# YC3122 register map
Series: ARMCM0; File version: 1.0
CPU: CM0 r1p0, little endian, no MPU, no FPU, 8 interrupt priority bits
Registers are 32-bit, read-write, reset 0x0 unless marked. A register's access mark holds for its fields unless they carry their own. Offsets are from the block's base; [hi:lo] are bit positions; {n}, {i} and the like mark numbered series.

## MMPU
Base 0x000D8080
0x00 CTRL_ID
  [31:0] VAL ro — MPU ID
0x04 CTRL
  [0] VAL — MPU使能
0x0C CTRL_FSR
  [31:0] VAL — [4:2] fault region [1:0] fault status
0x10 CTRL_FAR
  [31:0] VAL — fault address
0x14 PROTECTION 16-bit
  [15:0] VAL — protection15：0. 00：no access. 01：private only. 10：private + user read only. 11：Full Access
0x18 USER_START
  [31:0] VAL — 用户程序起始地址
{0x40+4i} REGION_BASE{i} (i=0..7)
  [31:0] VAL — [0]regionx_enable [20:6]. BASEx_REG
{0x60+4i} REGION_LIMIT{i} (i=0..7)
  [31:0] VAL — [20:6] LIMIT{i}_REG

## MWDT
Base 0x000F0000
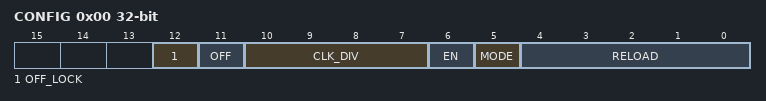
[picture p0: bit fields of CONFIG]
0x00 CONFIG
  [12] OFF_LOCK — wdt_off_lock. 1: wdt_off不起作用 0: wdt_off起作用
  [11] OFF — 关闭wdt wdt_off_lock为0,并且wdt_on为0时,设 置wdt_off为1,再设置wdt_off为0,可关闭w dt
  [10:7] CLK_DIV — hclk预分频,最大16分频,实际使用的时钟频率 是clk/(wdt_clk_div+1)
  [6] EN — 0 :WDT功能关闭. 1: WDT 功能打开.
  [5] MODE — 0 :复位 1:中断
  [4:0] RELOAD — WDT计数时长为(2^(wdt_preset-1 ))个hclk_div时钟周期
0x04 CNT
  [31:0] CNT ro — WDT CNT
0x08 IRQ_STATUS — WDT IRQ STATUS
  [0] STATE ro
0x08 KICK (alternate view of IRQ_STATUS) — WDT KICK, 必须写 0x5937
  [31:0] VALUE wo — WDT KICK,必须写 0x5937
0x0C CLEAR
  [0] CLEAR — 向这个寄存器中写1清除WDT 中断

## MTIM — 32 TIMER
Base 0x000F0C00
{0x0+4i} PERIOD[{i}] (i=0..17)
  [31:0] period
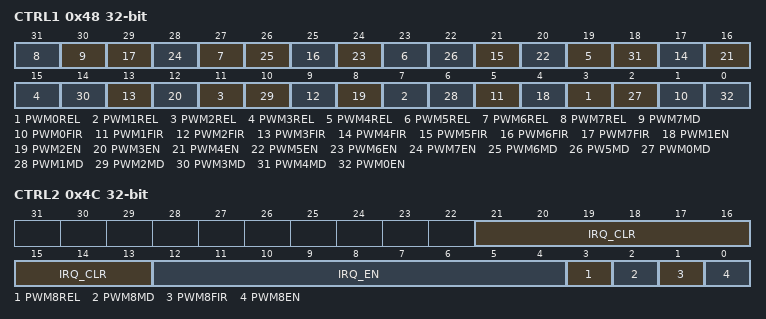
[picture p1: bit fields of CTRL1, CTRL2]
0x48 CTRL1 — pwm Control Register(0~7)
  [4n+3] PWM{n}REL (n=0..7) — TIMER AUTO RELOAD
  [30] PWM7MD — TIMER mode
  [4n+1] PWM{n}FIR (n=0..7) — TIMER initial level
  [4n] PWM{n}EN (n=1..7) — Enable or disable TIMER{n}
  [26] PWM6MD — TIMER mode
  [22] PW5MD — TIMER mode
  [4n+2] PWM{n}MD (n=0..4) — TIMER mode
  [0] PWM0EN — Enable or disable TIMER
0x4C CTRL2 — pwm Control Register(8)
  [21:13] IRQ_CLR — Clear interrupt control bits
  [12:4] IRQ_EN — The timer crresponds to the interrupt enable control bit
  [3] PWM8REL — TIMER AUTO RELOAD
  [2] PWM8MD — TIMER mode
  [1] PWM8FIR — TIMER initial level
  [0] PWM8EN — Enable or disable TIMER
{0x50+4i} CNT[{i}] (i=0..8) ro
  [31:0] cnt
0x74 IRQ_NUM — pwm IRQ status Register
  [8:0] PWM_IRQ_PEND ro — PWM_IRQ status

## MCRC
Base 0x000F8204
0x00 RESULT
  [31:0] VAL — 存放CRC运算的初值及结果
0x04 MASK
  [31:0] VAL — 计算掩码,不影响CRC最终运算结果
0x7C DATA 16-bit
  [15:0] VAL — 存放参与CRC运算的数据

## MSYSCTRL
Base 0x000F8520
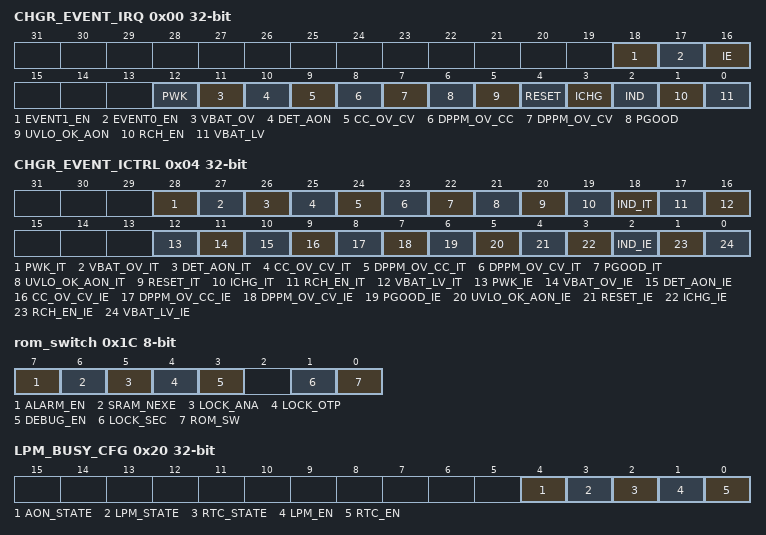
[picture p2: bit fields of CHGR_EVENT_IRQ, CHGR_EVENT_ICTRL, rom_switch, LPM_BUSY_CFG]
0x00 CHGR_EVENT_IRQ
  [18] EVENT1_EN — chgr_event[11:10]事件检测使能, 使能中断前必须先使能这一比特,power_key一直使能 ,无法更改
  [17] EVENT0_EN — chgr_event[9:0]事件检测使能,使能 中断前必须先使能这一比特
  [16] IE — chgr中断使能总开关
  [12] PWK — power key irq
  [11] VBAT_OV — ad_lpm_vbat_ov_flag
  [10] DET_AON — ad_lpm_chgr_in_det_aon
  [9] CC_OV_CV — ad_lpm_chgr_cc_ov_cv
  [8] DPPM_OV_CC — ad_lpm_chgr_dppm_ov_cc
  [7] DPPM_OV_CV — ad_lpm_chgr_dppm_ov_cv
  [6] PGOOD — ad_lpm_chgr_pgood
  [5] UVLO_OK_AON — ad_lpm_chgr_uvlo_ok_aon
  [4] RESET — ad_lpm_chgr_reset
  [3] ICHG — ad_lpm_chgr_state_ichg
  [2] IND — ad_lpm_chgr_state_ind
  [1] RCH_EN — ad_lpm_chgr_state_rch_en
  [0] VBAT_LV — ad_lpm_chgr_state_vbat_l v
0x04 CHGR_EVENT_ICTRL
  [28] PWK_IT — power_key
  [27] VBAT_OV_IT ro — ad_lpm_vbat_ov_flag
  [26] DET_AON_IT — ad_lpm_chgr_in_det_aon
  [25] CC_OV_CV_IT ro — ad_lpm_chgr_cc_ov_cv
  [24] DPPM_OV_CC_IT — ad_lpm_chgr_dppm_ov_cc
  [23] DPPM_OV_CV_IT ro — ad_lpm_chgr_dppm_ov_cv
  [22] PGOOD_IT — ad_lpm_chgr_pgood
  [21] UVLO_OK_AON_IT ro — ad_lpm_chgr_uvlo_ok_aon
  [20] RESET_IT — ad_lpm_chgr_reset
  [19] ICHG_IT ro — ad_lpm_chgr_state_ichg
  [18] IND_IT — ad_lpm_chgr_state_ind
  [17] RCH_EN_IT ro — ad_lpm_chgr_state_rch_en
  [16] VBAT_LV_IT — ad_lpm_chgr_state_vbat_l v 中断类型 0: 低电平 1: 高电平
  [12] PWK_IE — power_key
  [11] VBAT_OV_IE ro — ad_lpm_vbat_ov_flag
  [10] DET_AON_IE — ad_lpm_chgr_in_det_aon
  [9] CC_OV_CV_IE ro — ad_lpm_chgr_cc_ov_cv
  [8] DPPM_OV_CC_IE — ad_lpm_chgr_dppm_ov_cc
  [7] DPPM_OV_CV_IE ro — ad_lpm_chgr_dppm_ov_cv
  [6] PGOOD_IE — ad_lpm_chgr_pgood
  [5] UVLO_OK_AON_IE ro — ad_lpm_chgr_uvlo_ok_aon
  [4] RESET_IE — ad_lpm_chgr_reset
  [3] ICHG_IE ro — ad_lpm_chgr_state_ichg
  [2] IND_IE — ad_lpm_chgr_state_ind
  [1] RCH_EN_IE ro — ad_lpm_chgr_state_rch_en
  [0] VBAT_LV_IE — ad_lpm_chgr_state_vbat_l v 中断使能 0: 禁止 1: 使能
0x08 RNG_CTRL
{0xC+4i} RNG_DATA{i} (i=0..3)
  [31:0] VAL — 访问此寄存器可以获得随机数
0x1C rom_switch 8-bit
  [7] ALARM_EN — 报警使能 1：使能报警 0：失能报警
  [6] SRAM_NEXE — RAM不能跑程序,写0无效(产品阶段固定为1)
  [5] LOCK_ANA — 锁定模拟寄存器
  [4] LOCK_OTP — lock_otp 写1锁定寄存器 sfr_otphid_addr / sf r_otpuser_addr
  [3] DEBUG_EN — 使能DEBUG功能(产品阶段固定为0). 0: 失能debug功能; 1: 使能debug功能
  [1] LOCK_SEC — loc_sec
  [0] ROM_SW — 写1后置位,写0无效,模块复位后,恢复到0。(产 品阶段固定为1) 锁定的寄存器： ALARM_EN. BTM_EN gpio_ICE gpio_SWDAT sfr_ramkey_sel sfr_medcon_wr. QAES regs
0x20 LPM_BUSY_CFG
  [4] AON_STATE ro — 0: lpm/rtc register acce ss finish. 1: lpm/rtc register access o ngoing
  [3] LPM_STATE ro — 0: lpm access finish. 1: lpm access ongoing
  [2] RTC_STATE ro — 0: rtc access finish. 1: rtc access ongoing
  [1] LPM_EN — 0: 总线访问LPM时,不等待LPM完成直接返回 ,软件查询STATE标志确定是否访问完成 1: 总线访问LPM时,等待LPM访问完成才释放总线,软 件无须查询STATE标志
  [0] RTC_EN — 0: 总线访问RTC时,不等待RTC完成直接返回 ,软件查询STATE标志确定是否访问完成 1: 总线访问RTC时,等待LPM访问完成才释放总线,软 件无须查询STATE标志
0x24 LPM_RDATA
  [31:0] RDATA ro — lpm access read data
0x28 RTC_RDATA
  [31:0] RDATA ro — rtc access read data
0x2C AON_RDATA
  [31:0] RDATA ro — lpm/rtc access read data , the last read value of lpm or rtc
0x40 pwk_state
  [0] STATE ro — POWER_KEY按键状态
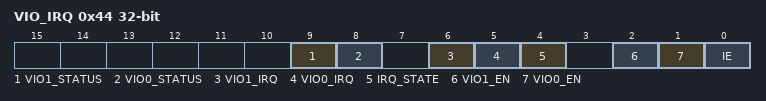
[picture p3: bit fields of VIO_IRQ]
0x44 VIO_IRQ
  [9] VIO1_STATUS ro — vio1 pgood状态 1: vio1 电源电压正常 0: vio1电源电压低于设定值
  [8] VIO0_STATUS ro — vio pgood状态 1: vio 电源电压正常 0: vio电源电压低于设定值
  [6] VIO1_IRQ — vio1 pgood irq 状态 1: vio1 电压低于配置值,vio1_pgood由高 变为低
  [5] VIO0_IRQ — vio pgood irq 状态 1: vio 电压低于配置值,vio_pgood由高变为 低
  [4] IRQ_STATE ro — vio pgood 中断总状态 1: vio0或vio1其中之一电压低于配置值
  [2] VIO1_EN — vio1 pgood 中断开关
  [1] VIO0_EN — vio0 pgood 中断开关
  [0] IE — vio 中断总开关
